# CM41x_M4 register map
Vendor: Analog Devices; Series: CM41x_M4; File version: 1p0
CPU: CM4 r0p1, little endian, MPU, FPU, 4 interrupt priority bits
Registers are 32-bit, read-write, reset 0x0 unless marked. A register's access mark holds for its fields unless they carry their own. Offsets are from the block's base; [hi:lo] are bit positions.

## SYSBLK1 — Pads Controller
Base 0x40000000
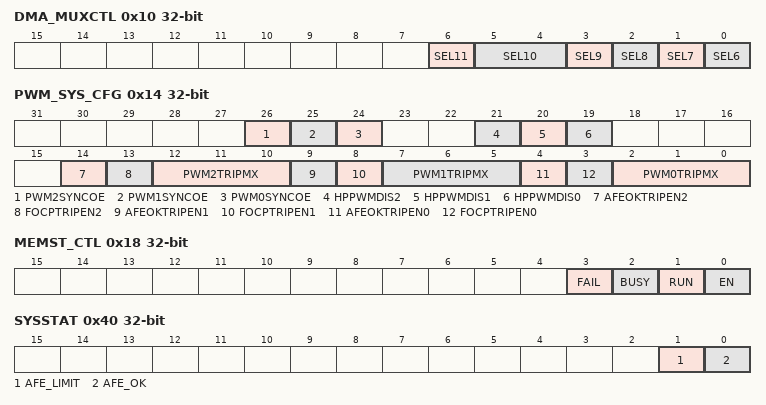
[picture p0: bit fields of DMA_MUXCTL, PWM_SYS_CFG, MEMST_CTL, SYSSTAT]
0x10 DMA_MUXCTL — Peripheral DMA Multiplexer Control
  [6] SEL11 — Mux select for DMA11
    0=SPORT0_B_DMA (Select SPORT[0] B_DMA port); 1=UART4_RXDMA (Select UART[4] RXDMA port)
  [5:4] SEL10 — Mux select for DMA10
    0=HAE0_RXDMA_CH1 (Select HAE[0] RXDMA_CH1 port); 1=SPORT0_A_DMA (Select SPORT[0] A_DMA port); 2=UART4_TXDMA (Select UART[4] TXDMA port)
  [3] SEL9 — Mux select for DMA9
    0=HAE0_TXDMA (Select HAE[0] TXDMA port); 1=UART3_RXDMA (Select UART[3] RXDMA port)
  [2] SEL8 — Mux select for DMA8
    0=HAE0_RXDMA_CH0 (Select HAE[0] RXDMA_CH0 port); 1=UART3_TXDMA (Select UART[3] TXDMA port)
  [1] SEL7 — Mux select for DMA7
    0=SPI1_RXDMA (Select SPI[1] RXDMA port); 1=UART2_RXDMA (Select UART[2] RXDMA port)
  [0] SEL6 — Mux select for DMA6
    0=SPI1_TXDMA (Select SPI[1] TXDMA port); 1=UART2_TXDMA (Select UART[2] TXDMA port)
0x14 PWM_SYS_CFG — PWM System Configuration Register
  [26] PWM2SYNCOE range 0x00000000..0x00000001 — PWM2 SYNC OUT Secondary Enable
  [25] PWM1SYNCOE range 0x00000000..0x00000001 — PWM1 SYNC OUT Secondary Enable
  [24] PWM0SYNCOE range 0x00000000..0x00000001 — PWM0 SYNC OUT Secondary Enable
  [21] HPPWMDIS2 range 0x00000000..0x00000001 — High Precision PWM Block2 Disable
  [20] HPPWMDIS1 range 0x00000000..0x00000001 — High Precision PWM Block1 Disable
  [19] HPPWMDIS0 range 0x00000000..0x00000001 — High Precision PWM Block0 Disable
  [14] AFEOKTRIPEN2 range 0x00000000..0x00000001 — Analog Front End Not OK PWM Trip Enable 2
  [13] FOCPTRIPEN2 range 0x00000000..0x00000001 — Fast Over Current Protection PWM Trip Enable 2
  [12:10] PWM2TRIPMX range 0x00000000..0x00000007 — PWM2 Trip Multiplexer Select
  [9] AFEOKTRIPEN1 range 0x00000000..0x00000001 — Analog Front End Not OK PWM Trip Enable 1
  [8] FOCPTRIPEN1 range 0x00000000..0x00000001 — Fast Over Current Protection PWM Trip Enable 1
  [7:5] PWM1TRIPMX range 0x00000000..0x00000007 — PWM1 Trip Multiplexer Select
  [4] AFEOKTRIPEN0 range 0x00000000..0x00000001 — Analog Front End Not OK PWM Trip Enable 0
  [3] FOCPTRIPEN0 range 0x00000000..0x00000001 — Fast Over Current Protection PWM Trip Enable 0
  [2:0] PWM0TRIPMX range 0x00000000..0x00000007 — PWM0 Trip Multiplexer Select
0x18 MEMST_CTL — Memory Self-Test Control Register
  [3] FAIL ro — Test Pass/Fail Status
  [2] BUSY ro — Busy Status
  [1] RUN range 0x00000000..0x00000001 — Run Control
  [0] EN — Memory Self-Test Enable
0x1C SINC_TEST
  [3:0] EN range 0x00000000..0x0000000F — SINC Test Enable
0x40 SYSSTAT — System Status Register
  [1] AFE_LIMIT ro — Status of AFE_LIMIT signal
  [0] AFE_OK ro — Status of AFE_OK Signal
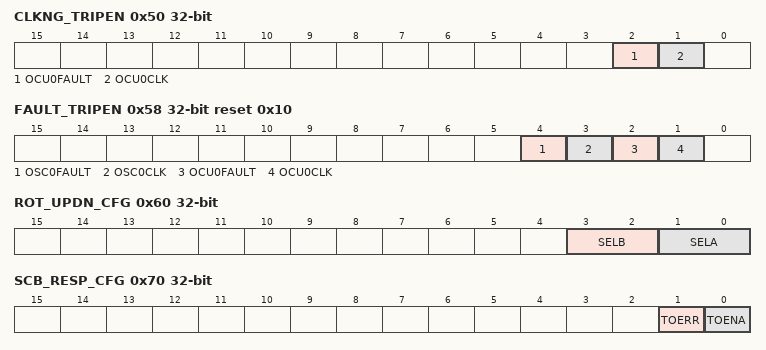
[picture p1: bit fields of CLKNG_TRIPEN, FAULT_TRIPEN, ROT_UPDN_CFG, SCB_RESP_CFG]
0x50 CLKNG_TRIPEN — Clock Not Good Trip Register
  [2] OCU0FAULT range 0x00000000..0x00000001 — Oscillator Compare Unit Asynchronous Fault Trip Enable
  [1] OCU0CLK range 0x00000000..0x00000001 — Oscillator Compare Unit Dead Clock Trip Enable
0x58 FAULT_TRIPEN reset 0x10 — Fault Trip Register
  [4] OSC0FAULT range 0x00000000..0x00000001 — System Oscillator Asynchronous Fault Trip Enable
  [3] OSC0CLK range 0x00000000..0x00000001 — System Oscillator Clock No Good Trip Enable
  [2] OCU0FAULT range 0x00000000..0x00000001 — Oscillator Compare Unit Asynchronous Fault Trip Enable
  [1] OCU0CLK range 0x00000000..0x00000001 — Oscillator Compare Unit Dead Clock Trip Enable
0x60 ROT_UPDN_CFG — Rotary Counter Up/Down Configuration Register
  [3:2] SELB — Select Phase B
    0=PAD_to_B (Select Pad as input to Rotary Counter); 1=PAD2_to_B (Select Pad as input to Rotary Counter); 2=TRIG_to_B (Select Trigger Slave as input to Rotary Counter); 3=LBA_to_B (Select LBA as input to Rotary Counter)
  [1:0] SELA — Select Phase A
    0=PAD_to_A (Select Pad as input to Rotary Counter); 1=PAD2_to_A (Select Pad as input to Rotary Counter); 2=TRIG_to_A (Select Trigger Slave as input to Rotary Counter); 3=LBA_to_A (Select LBA as input to Rotary Counter)
0x70 SCB_RESP_CFG — SCB Response Configuration Register
  [1] TOERR — Timeout Error
  [0] TOENA — Enable SCB Timeout Interrupt
0x74 SCB_TIMEOUT_VALUE
  [15:0] DATA range 0x00000000..0x0000FFFF — Timeout Value
0x80 ENG_MODE_CFG0 — Engineering Mode Configuration Register 0
  [17] LBA_COMB_MODE range 0x00000000..0x00000001 — LBA Combinatorial mode
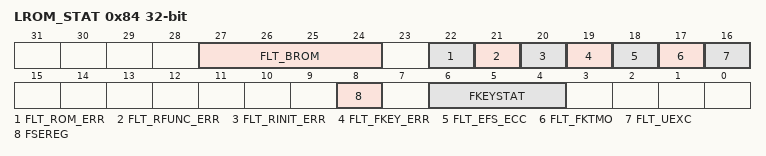
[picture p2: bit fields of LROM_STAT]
0x84 LROM_STAT — Logic ROM Status Register
  [27:24] FLT_BROM range 0x00000000..0x0000000F — Boot ROM Fault Code
  [22] FLT_ROM_ERR range 0x00000000..0x00000001 — CRC Error in Array Boot ROM
  [21] FLT_RFUNC_ERR range 0x00000000..0x00000001 — CRC Error in RFUNC Code Section
  [20] FLT_RINIT_ERR range 0x00000000..0x00000001 — CRC Error in RINIT Structure
  [19] FLT_FKEY_ERR range 0x00000000..0x00000001 — Flash Key Invalid
  [18] FLT_EFS_ECC range 0x00000000..0x00000001 — Configuration ECC Error
  [17] FLT_FKTMO range 0x00000000..0x00000001 — Configuration/Flash Key Timeout
  [16] FLT_UEXC range 0x00000000..0x00000001 — Unexpected Exception Fault
  [8] FSEREG ro — FSEREG Security Enable
  [6:4] FKEYSTAT ro — Flash Key Status
    0=KEYRD_PEND (Flash Key read process is pending); 1=KEY_INVALID (Flash key is invalid); 2=KEY_BLANK (Flash Key is unprogrammed but contrast code is valid); 3=KEY_VALID (Flash key is programmed and is valid); 6=KEY_UNINIT (The flash contrast code is blank or invalid.)
